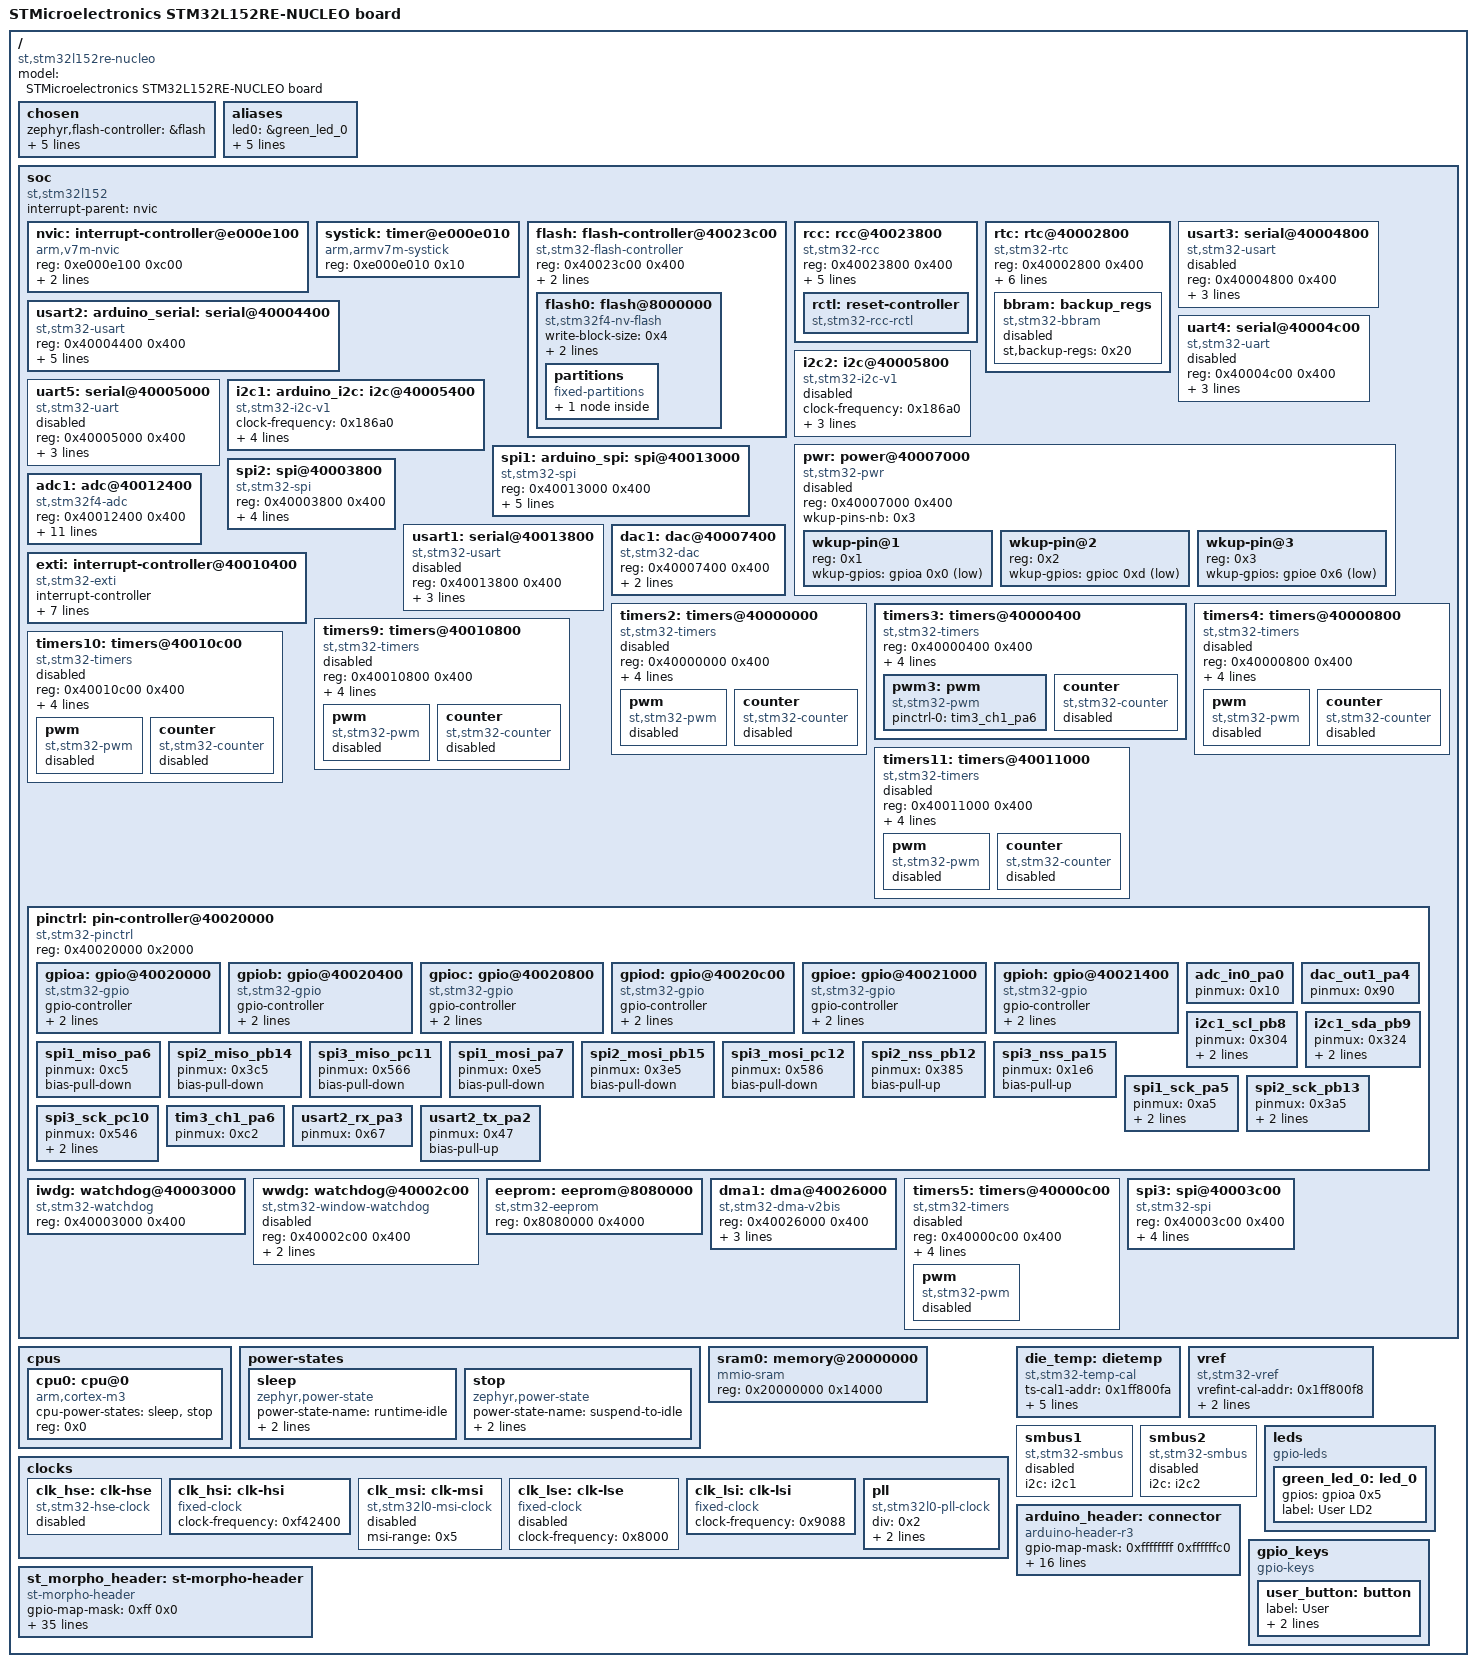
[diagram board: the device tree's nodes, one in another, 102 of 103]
/dts-v1/;

/* node '/' defined in zephyr\dts\common\skeleton.dtsi:9 */
/ {
	#address-cells = < 0x1 >;                              /* in zephyr\dts\common\skeleton.dtsi:10 */
	#size-cells = < 0x1 >;                                 /* in zephyr\dts\common\skeleton.dtsi:11 */
	model = "STMicroelectronics STM32L152RE-NUCLEO board"; /* in zephyr\boards\st\nucleo_l152re\nucleo_l152re.dts:15 */
	compatible = "st,stm32l152re-nucleo";                  /* in zephyr\boards\st\nucleo_l152re\nucleo_l152re.dts:16 */

	/* node '/chosen' defined in zephyr\dts\common\skeleton.dtsi:13 */
	chosen {
		zephyr,flash-controller = &flash;  /* in zephyr\dts\arm\st\l1\stm32l1.dtsi:24 */
		zephyr,cortex-m-idle-timer = &rtc; /* in zephyr\dts\arm\st\l1\stm32l1.dtsi:25 */
		zephyr,console = &usart2;          /* in zephyr\boards\st\nucleo_l152re\nucleo_l152re.dts:19 */
		zephyr,shell-uart = &usart2;       /* in zephyr\boards\st\nucleo_l152re\nucleo_l152re.dts:20 */
		zephyr,sram = &sram0;              /* in zephyr\boards\st\nucleo_l152re\nucleo_l152re.dts:21 */
		zephyr,flash = &flash0;            /* in zephyr\boards\st\nucleo_l152re\nucleo_l152re.dts:22 */
	};

	/* node '/aliases' defined in zephyr\dts\common\skeleton.dtsi:15 */
	aliases {
		led0 = &green_led_0;   /* in zephyr\boards\st\nucleo_l152re\nucleo_l152re.dts:45 */
		sw0 = &user_button;    /* in zephyr\boards\st\nucleo_l152re\nucleo_l152re.dts:46 */
		eeprom-0 = &eeprom;    /* in zephyr\boards\st\nucleo_l152re\nucleo_l152re.dts:47 */
		watchdog0 = &iwdg;     /* in zephyr\boards\st\nucleo_l152re\nucleo_l152re.dts:48 */
		die-temp0 = &die_temp; /* in zephyr\boards\st\nucleo_l152re\nucleo_l152re.dts:49 */
		volt-sensor0 = &vref;  /* in zephyr\boards\st\nucleo_l152re\nucleo_l152re.dts:50 */
	};

	/* node '/soc' defined in zephyr\dts\arm\armv7-m.dtsi:6 */
	soc {
		#address-cells = < 0x1 >;     /* in zephyr\dts\arm\armv7-m.dtsi:7 */
		#size-cells = < 0x1 >;        /* in zephyr\dts\arm\armv7-m.dtsi:8 */
		interrupt-parent = < &nvic >; /* in zephyr\dts\arm\armv7-m.dtsi:10 */
		ranges;                       /* in zephyr\dts\arm\armv7-m.dtsi:11 */
		compatible = "st,stm32l152",
		             "st,stm32l1",
		             "simple-bus";    /* in zephyr\dts\arm\st\l1\stm32l152.dtsi:15 */

		/* node '/soc/interrupt-controller@e000e100' defined in zephyr\dts\arm\armv7-m.dtsi:13 */
		nvic: interrupt-controller@e000e100 {
			#address-cells = < 0x1 >;            /* in zephyr\dts\arm\armv7-m.dtsi:14 */
			compatible = "arm,v7m-nvic";         /* in zephyr\dts\arm\armv7-m.dtsi:15 */
			reg = < 0xe000e100 0xc00 >;          /* in zephyr\dts\arm\armv7-m.dtsi:16 */
			interrupt-controller;                /* in zephyr\dts\arm\armv7-m.dtsi:17 */
			#interrupt-cells = < 0x2 >;          /* in zephyr\dts\arm\armv7-m.dtsi:18 */
			arm,num-irq-priority-bits = < 0x4 >; /* in zephyr\dts\arm\st\l1\stm32l1.dtsi:561 */
			phandle = < 0x1 >;                   /* in zephyr\dts\arm\armv7-m.dtsi:10 */
		};

		/* node '/soc/timer@e000e010' defined in zephyr\dts\arm\armv7-m.dtsi:21 */
		systick: timer@e000e010 {
			compatible = "arm,armv7m-systick"; /* in zephyr\dts\arm\armv7-m.dtsi:22 */
			reg = < 0xe000e010 0x10 >;         /* in zephyr\dts\arm\armv7-m.dtsi:23 */
		};

		/* node '/soc/flash-controller@40023c00' defined in zephyr\dts\arm\st\l1\stm32l1.dtsi:103 */
		flash: flash-controller@40023c00 {
			compatible = "st,stm32-flash-controller",
			             "st,stm32f1-flash-controller"; /* in zephyr\dts\arm\st\l1\stm32l1.dtsi:104 */
			reg = < 0x40023c00 0x400 >;                 /* in zephyr\dts\arm\st\l1\stm32l1.dtsi:105 */
			interrupts = < 0x4 0x0 >;                   /* in zephyr\dts\arm\st\l1\stm32l1.dtsi:106 */
			clocks = < &rcc 0x1c 0x8000 >;              /* in zephyr\dts\arm\st\l1\stm32l1.dtsi:107 */
			#address-cells = < 0x1 >;                   /* in zephyr\dts\arm\st\l1\stm32l1.dtsi:109 */
			#size-cells = < 0x1 >;                      /* in zephyr\dts\arm\st\l1\stm32l1.dtsi:110 */

			/* node '/soc/flash-controller@40023c00/flash@8000000' defined in zephyr\dts\arm\st\l1\stm32l1.dtsi:112 */
			flash0: flash@8000000 {
				compatible = "st,stm32f4-nv-flash",
				             "st,stm32-nv-flash",
				             "soc-nv-flash";        /* in zephyr\dts\arm\st\l1\stm32l1.dtsi:113 */
				write-block-size = < 0x4 >;         /* in zephyr\dts\arm\st\l1\stm32l1.dtsi:116 */
				max-erase-time = < 0x4 >;           /* in zephyr\dts\arm\st\l1\stm32l1.dtsi:119 */
				reg = < 0x8000000 0x80000 >;        /* in zephyr\dts\arm\st\l1\stm32l152Xe.dtsi:18 */

				/* node '/soc/flash-controller@40023c00/flash@8000000/partitions' defined in zephyr\boards\st\nucleo_l152re\nucleo_l152re.dts:145 */
				partitions {
					compatible = "fixed-partitions"; /* in zephyr\boards\st\nucleo_l152re\nucleo_l152re.dts:146 */
					#address-cells = < 0x1 >;        /* in zephyr\boards\st\nucleo_l152re\nucleo_l152re.dts:147 */
					#size-cells = < 0x1 >;           /* in zephyr\boards\st\nucleo_l152re\nucleo_l152re.dts:148 */

					/* node '/soc/flash-controller@40023c00/flash@8000000/partitions/partition@7e000' defined in zephyr\boards\st\nucleo_l152re\nucleo_l152re.dts:151 */
					storage_partition: partition@7e000 {
						label = "storage";        /* in zephyr\boards\st\nucleo_l152re\nucleo_l152re.dts:152 */
						reg = < 0x7e000 0x2000 >; /* in zephyr\boards\st\nucleo_l152re\nucleo_l152re.dts:153 */
					};
				};
			};
		};

		/* node '/soc/rcc@40023800' defined in zephyr\dts\arm\st\l1\stm32l1.dtsi:123 */
		rcc: rcc@40023800 {
			compatible = "st,stm32-rcc";     /* in zephyr\dts\arm\st\l1\stm32l1.dtsi:124 */
			#clock-cells = < 0x2 >;          /* in zephyr\dts\arm\st\l1\stm32l1.dtsi:125 */
			reg = < 0x40023800 0x400 >;      /* in zephyr\dts\arm\st\l1\stm32l1.dtsi:126 */
			clocks = < &pll >;               /* in zephyr\boards\st\nucleo_l152re\nucleo_l152re.dts:70 */
			clock-frequency = < 0x1e84800 >; /* in zephyr\boards\st\nucleo_l152re\nucleo_l152re.dts:71 */
			ahb-prescaler = < 0x1 >;         /* in zephyr\boards\st\nucleo_l152re\nucleo_l152re.dts:72 */
			apb1-prescaler = < 0x1 >;        /* in zephyr\boards\st\nucleo_l152re\nucleo_l152re.dts:73 */
			apb2-prescaler = < 0x1 >;        /* in zephyr\boards\st\nucleo_l152re\nucleo_l152re.dts:74 */
			phandle = < 0x2 >;               /* in zephyr\dts\arm\st\l1\stm32l1.dtsi:107 */

			/* node '/soc/rcc@40023800/reset-controller' defined in zephyr\dts\arm\st\l1\stm32l1.dtsi:128 */
			rctl: reset-controller {
				compatible = "st,stm32-rcc-rctl"; /* in zephyr\dts\arm\st\l1\stm32l1.dtsi:129 */
				#reset-cells = < 0x1 >;           /* in zephyr\dts\arm\st\l1\stm32l1.dtsi:130 */
				phandle = < 0x4 >;                /* in zephyr\dts\arm\st\l1\stm32l1.dtsi:149 */
			};
		};

		/* node '/soc/rtc@40002800' defined in zephyr\dts\arm\st\l1\stm32l1.dtsi:134 */
		rtc: rtc@40002800 {
			compatible = "st,stm32-rtc";       /* in zephyr\dts\arm\st\l1\stm32l1.dtsi:135 */
			reg = < 0x40002800 0x400 >;        /* in zephyr\dts\arm\st\l1\stm32l1.dtsi:136 */
			interrupts = < 0x29 0x0 >;         /* in zephyr\dts\arm\st\l1\stm32l1.dtsi:137 */
			prescaler = < 0x8000 >;            /* in zephyr\dts\arm\st\l1\stm32l1.dtsi:139 */
			alarms-count = < 0x2 >;            /* in zephyr\dts\arm\st\l1\stm32l1.dtsi:140 */
			alrm-exti-line = < 0x11 >;         /* in zephyr\dts\arm\st\l1\stm32l1.dtsi:141 */
			clocks = < &rcc 0x24 0x10000000 >,
			         < &rcc 0x3 0x10d00034 >;  /* in zephyr\boards\st\nucleo_l152re\nucleo_l152re.dts:121 */
			status = "okay";                   /* in zephyr\boards\st\nucleo_l152re\nucleo_l152re.dts:123 */

			/* node '/soc/rtc@40002800/backup_regs' defined in zephyr\dts\arm\st\l1\stm32l152Xe.dtsi:55 */
			bbram: backup_regs {
				compatible = "st,stm32-bbram"; /* in zephyr\dts\arm\st\l1\stm32l152Xe.dtsi:56 */
				st,backup-regs = < 0x20 >;     /* in zephyr\dts\arm\st\l1\stm32l152Xe.dtsi:57 */
				status = "disabled";           /* in zephyr\dts\arm\st\l1\stm32l152Xe.dtsi:58 */
			};
		};

		/* node '/soc/serial@40004400' defined in zephyr\dts\arm\st\l1\stm32l1.dtsi:145 */
		usart2: arduino_serial: serial@40004400 {
			compatible = "st,stm32-usart",
			             "st,stm32-uart";                  /* in zephyr\dts\arm\st\l1\stm32l1.dtsi:146 */
			reg = < 0x40004400 0x400 >;                    /* in zephyr\dts\arm\st\l1\stm32l1.dtsi:147 */
			clocks = < &rcc 0x24 0x20000 >;                /* in zephyr\dts\arm\st\l1\stm32l1.dtsi:148 */
			resets = < &rctl 0x311 >;                      /* in zephyr\dts\arm\st\l1\stm32l1.dtsi:149 */
			interrupts = < 0x26 0x0 >;                     /* in zephyr\dts\arm\st\l1\stm32l1.dtsi:150 */
			pinctrl-0 = < &usart2_tx_pa2 &usart2_rx_pa3 >; /* in zephyr\boards\st\nucleo_l152re\nucleo_l152re.dts:78 */
			pinctrl-names = "default";                     /* in zephyr\boards\st\nucleo_l152re\nucleo_l152re.dts:79 */
			current-speed = < 0x1c200 >;                   /* in zephyr\boards\st\nucleo_l152re\nucleo_l152re.dts:80 */
			status = "okay";                               /* in zephyr\boards\st\nucleo_l152re\nucleo_l152re.dts:81 */
		};

		/* node '/soc/serial@40004800' defined in zephyr\dts\arm\st\l1\stm32l1.dtsi:154 */
		usart3: serial@40004800 {
			compatible = "st,stm32-usart",
			             "st,stm32-uart";   /* in zephyr\dts\arm\st\l1\stm32l1.dtsi:155 */
			reg = < 0x40004800 0x400 >;     /* in zephyr\dts\arm\st\l1\stm32l1.dtsi:156 */
			clocks = < &rcc 0x24 0x40000 >; /* in zephyr\dts\arm\st\l1\stm32l1.dtsi:157 */
			resets = < &rctl 0x312 >;       /* in zephyr\dts\arm\st\l1\stm32l1.dtsi:158 */
			interrupts = < 0x27 0x0 >;      /* in zephyr\dts\arm\st\l1\stm32l1.dtsi:159 */
			status = "disabled";            /* in zephyr\dts\arm\st\l1\stm32l1.dtsi:160 */
		};

		/* node '/soc/serial@40004c00' defined in zephyr\dts\arm\st\l1\stm32l1.dtsi:163 */
		uart4: serial@40004c00 {
			compatible = "st,stm32-uart";   /* in zephyr\dts\arm\st\l1\stm32l1.dtsi:164 */
			reg = < 0x40004c00 0x400 >;     /* in zephyr\dts\arm\st\l1\stm32l1.dtsi:165 */
			clocks = < &rcc 0x24 0x80000 >; /* in zephyr\dts\arm\st\l1\stm32l1.dtsi:166 */
			resets = < &rctl 0x313 >;       /* in zephyr\dts\arm\st\l1\stm32l1.dtsi:167 */
			interrupts = < 0x30 0x0 >;      /* in zephyr\dts\arm\st\l1\stm32l1.dtsi:168 */
			status = "disabled";            /* in zephyr\dts\arm\st\l1\stm32l1.dtsi:169 */
		};

		/* node '/soc/serial@40005000' defined in zephyr\dts\arm\st\l1\stm32l1.dtsi:172 */
		uart5: serial@40005000 {
			compatible = "st,stm32-uart";    /* in zephyr\dts\arm\st\l1\stm32l1.dtsi:173 */
			reg = < 0x40005000 0x400 >;      /* in zephyr\dts\arm\st\l1\stm32l1.dtsi:174 */
			clocks = < &rcc 0x24 0x100000 >; /* in zephyr\dts\arm\st\l1\stm32l1.dtsi:175 */
			resets = < &rctl 0x314 >;        /* in zephyr\dts\arm\st\l1\stm32l1.dtsi:176 */
			interrupts = < 0x31 0x0 >;       /* in zephyr\dts\arm\st\l1\stm32l1.dtsi:177 */
			status = "disabled";             /* in zephyr\dts\arm\st\l1\stm32l1.dtsi:178 */
		};

		/* node '/soc/i2c@40005400' defined in zephyr\dts\arm\st\l1\stm32l1.dtsi:181 */
		i2c1: arduino_i2c: i2c@40005400 {
			compatible = "st,stm32-i2c-v1";              /* in zephyr\dts\arm\st\l1\stm32l1.dtsi:182 */
			clock-frequency = < 0x186a0 >;               /* in zephyr\dts\arm\st\l1\stm32l1.dtsi:183 */
			#address-cells = < 0x1 >;                    /* in zephyr\dts\arm\st\l1\stm32l1.dtsi:184 */
			#size-cells = < 0x0 >;                       /* in zephyr\dts\arm\st\l1\stm32l1.dtsi:185 */
			reg = < 0x40005400 0x400 >;                  /* in zephyr\dts\arm\st\l1\stm32l1.dtsi:186 */
			clocks = < &rcc 0x24 0x200000 >;             /* in zephyr\dts\arm\st\l1\stm32l1.dtsi:187 */
			interrupts = < 0x1f 0x0 >,
			             < 0x20 0x0 >;                   /* in zephyr\dts\arm\st\l1\stm32l1.dtsi:188 */
			interrupt-names = "event",
			                  "error";                   /* in zephyr\dts\arm\st\l1\stm32l1.dtsi:189 */
			pinctrl-0 = < &i2c1_scl_pb8 &i2c1_sda_pb9 >; /* in zephyr\boards\st\nucleo_l152re\nucleo_l152re.dts:85 */
			pinctrl-names = "default";                   /* in zephyr\boards\st\nucleo_l152re\nucleo_l152re.dts:86 */
			status = "okay";                             /* in zephyr\boards\st\nucleo_l152re\nucleo_l152re.dts:87 */
			phandle = < 0x1f >;                          /* in zephyr\dts\arm\st\l1\stm32l1.dtsi:547 */
		};

		/* node '/soc/i2c@40005800' defined in zephyr\dts\arm\st\l1\stm32l1.dtsi:193 */
		i2c2: i2c@40005800 {
			compatible = "st,stm32-i2c-v1";  /* in zephyr\dts\arm\st\l1\stm32l1.dtsi:194 */
			clock-frequency = < 0x186a0 >;   /* in zephyr\dts\arm\st\l1\stm32l1.dtsi:195 */
			#address-cells = < 0x1 >;        /* in zephyr\dts\arm\st\l1\stm32l1.dtsi:196 */
			#size-cells = < 0x0 >;           /* in zephyr\dts\arm\st\l1\stm32l1.dtsi:197 */
			reg = < 0x40005800 0x400 >;      /* in zephyr\dts\arm\st\l1\stm32l1.dtsi:198 */
			clocks = < &rcc 0x24 0x400000 >; /* in zephyr\dts\arm\st\l1\stm32l1.dtsi:199 */
			interrupts = < 0x21 0x0 >,
			             < 0x22 0x0 >;       /* in zephyr\dts\arm\st\l1\stm32l1.dtsi:200 */
			interrupt-names = "event",
			                  "error";       /* in zephyr\dts\arm\st\l1\stm32l1.dtsi:201 */
			status = "disabled";             /* in zephyr\dts\arm\st\l1\stm32l1.dtsi:202 */
			phandle = < 0x20 >;              /* in zephyr\dts\arm\st\l1\stm32l1.dtsi:555 */
		};

		/* node '/soc/power@40007000' defined in zephyr\dts\arm\st\l1\stm32l1.dtsi:205 */
		pwr: power@40007000 {
			compatible = "st,stm32-pwr"; /* in zephyr\dts\arm\st\l1\stm32l1.dtsi:206 */
			reg = < 0x40007000 0x400 >;  /* in zephyr\dts\arm\st\l1\stm32l1.dtsi:207 */
			status = "disabled";         /* in zephyr\dts\arm\st\l1\stm32l1.dtsi:208 */
			wkup-pins-nb = < 0x3 >;      /* in zephyr\dts\arm\st\l1\stm32l1.dtsi:210 */
			#address-cells = < 0x1 >;    /* in zephyr\dts\arm\st\l1\stm32l1.dtsi:212 */
			#size-cells = < 0x0 >;       /* in zephyr\dts\arm\st\l1\stm32l1.dtsi:213 */

			/* node '/soc/power@40007000/wkup-pin@1' defined in zephyr\dts\arm\st\l1\stm32l1.dtsi:215 */
			wkup-pin@1 {
				reg = < 0x1 >;                   /* in zephyr\dts\arm\st\l1\stm32l1.dtsi:216 */
				wkup-gpios = < &gpioa 0x0 0x1 >; /* in zephyr\dts\arm\st\l1\stm32l1.dtsi:217 */
			};

			/* node '/soc/power@40007000/wkup-pin@2' defined in zephyr\dts\arm\st\l1\stm32l1.dtsi:220 */
			wkup-pin@2 {
				reg = < 0x2 >;                   /* in zephyr\dts\arm\st\l1\stm32l1.dtsi:221 */
				wkup-gpios = < &gpioc 0xd 0x1 >; /* in zephyr\dts\arm\st\l1\stm32l1.dtsi:222 */
			};

			/* node '/soc/power@40007000/wkup-pin@3' defined in zephyr\dts\arm\st\l1\stm32l1.dtsi:225 */
			wkup-pin@3 {
				reg = < 0x3 >;                   /* in zephyr\dts\arm\st\l1\stm32l1.dtsi:226 */
				wkup-gpios = < &gpioe 0x6 0x1 >; /* in zephyr\dts\arm\st\l1\stm32l1.dtsi:227 */
			};
		};

		/* node '/soc/spi@40013000' defined in zephyr\dts\arm\st\l1\stm32l1.dtsi:231 */
		spi1: arduino_spi: spi@40013000 {
			compatible = "st,stm32-spi";                                 /* in zephyr\dts\arm\st\l1\stm32l1.dtsi:232 */
			#address-cells = < 0x1 >;                                    /* in zephyr\dts\arm\st\l1\stm32l1.dtsi:233 */
			#size-cells = < 0x0 >;                                       /* in zephyr\dts\arm\st\l1\stm32l1.dtsi:234 */
			reg = < 0x40013000 0x400 >;                                  /* in zephyr\dts\arm\st\l1\stm32l1.dtsi:235 */
			clocks = < &rcc 0x20 0x1000 >;                               /* in zephyr\dts\arm\st\l1\stm32l1.dtsi:236 */
			interrupts = < 0x23 0x0 >;                                   /* in zephyr\dts\arm\st\l1\stm32l1.dtsi:237 */
			pinctrl-0 = < &spi1_sck_pa5 &spi1_miso_pa6 &spi1_mosi_pa7 >; /* in zephyr\boards\st\nucleo_l152re\nucleo_l152re.dts:91 */
			pinctrl-names = "default";                                   /* in zephyr\boards\st\nucleo_l152re\nucleo_l152re.dts:92 */
			cs-gpios = < &gpiob 0x6 0x11 >;                              /* in zephyr\boards\st\nucleo_l152re\nucleo_l152re.dts:93 */
			status = "okay";                                             /* in zephyr\boards\st\nucleo_l152re\nucleo_l152re.dts:94 */
		};

		/* node '/soc/spi@40003800' defined in zephyr\dts\arm\st\l1\stm32l1.dtsi:241 */
		spi2: spi@40003800 {
			compatible = "st,stm32-spi";                                                   /* in zephyr\dts\arm\st\l1\stm32l1.dtsi:242 */
			#address-cells = < 0x1 >;                                                      /* in zephyr\dts\arm\st\l1\stm32l1.dtsi:243 */
			#size-cells = < 0x0 >;                                                         /* in zephyr\dts\arm\st\l1\stm32l1.dtsi:244 */
			reg = < 0x40003800 0x400 >;                                                    /* in zephyr\dts\arm\st\l1\stm32l1.dtsi:245 */
			clocks = < &rcc 0x24 0x4000 >;                                                 /* in zephyr\dts\arm\st\l1\stm32l1.dtsi:246 */
			interrupts = < 0x24 0x0 >;                                                     /* in zephyr\dts\arm\st\l1\stm32l1.dtsi:247 */
			pinctrl-0 = < &spi2_nss_pb12 &spi2_sck_pb13 &spi2_miso_pb14 &spi2_mosi_pb15 >; /* in zephyr\boards\st\nucleo_l152re\nucleo_l152re.dts:98 */
			pinctrl-names = "default";                                                     /* in zephyr\boards\st\nucleo_l152re\nucleo_l152re.dts:100 */
			status = "okay";                                                               /* in zephyr\boards\st\nucleo_l152re\nucleo_l152re.dts:101 */
		};

		/* node '/soc/serial@40013800' defined in zephyr\dts\arm\st\l1\stm32l1.dtsi:251 */
		usart1: serial@40013800 {
			compatible = "st,stm32-usart",
			             "st,stm32-uart";  /* in zephyr\dts\arm\st\l1\stm32l1.dtsi:252 */
			reg = < 0x40013800 0x400 >;    /* in zephyr\dts\arm\st\l1\stm32l1.dtsi:253 */
			clocks = < &rcc 0x20 0x4000 >; /* in zephyr\dts\arm\st\l1\stm32l1.dtsi:254 */
			resets = < &rctl 0x28e >;      /* in zephyr\dts\arm\st\l1\stm32l1.dtsi:255 */
			interrupts = < 0x25 0x0 >;     /* in zephyr\dts\arm\st\l1\stm32l1.dtsi:256 */
			status = "disabled";           /* in zephyr\dts\arm\st\l1\stm32l1.dtsi:257 */
		};

		/* node '/soc/adc@40012400' defined in zephyr\dts\arm\st\l1\stm32l1.dtsi:260 */
		adc1: adc@40012400 {
			compatible = "st,stm32f4-adc",
			             "st,stm32-adc";                                 /* in zephyr\dts\arm\st\l1\stm32l1.dtsi:261 */
			reg = < 0x40012400 0x400 >;                                  /* in zephyr\dts\arm\st\l1\stm32l1.dtsi:262 */
			clocks = < &rcc 0x20 0x200 >,
			         < &rcc 0x5 0xff >;                                  /* in zephyr\dts\arm\st\l1\stm32l1.dtsi:263 */
			interrupts = < 0x12 0x0 >;                                   /* in zephyr\dts\arm\st\l1\stm32l1.dtsi:265 */
			#io-channel-cells = < 0x1 >;                                 /* in zephyr\dts\arm\st\l1\stm32l1.dtsi:267 */
			resolutions = < 0x607804 0x517804 0x427804 0x337804 >;       /* in zephyr\dts\arm\st\l1\stm32l1.dtsi:268 */
			sampling-times = < 0x4 0x9 0x10 0x18 0x30 0x60 0xc0 0x180 >; /* in zephyr\dts\arm\st\l1\stm32l1.dtsi:272 */
			st,adc-sequencer = "FULLY_CONFIGURABLE";                     /* in zephyr\dts\arm\st\l1\stm32l1.dtsi:274 */
			st,adc-oversampler = "OVERSAMPLER_NONE";                     /* in zephyr\dts\arm\st\l1\stm32l1.dtsi:275 */
			pinctrl-0 = < &adc_in0_pa0 >;                                /* in zephyr\boards\st\nucleo_l152re\nucleo_l152re.dts:127 */
			pinctrl-names = "default";                                   /* in zephyr\boards\st\nucleo_l152re\nucleo_l152re.dts:128 */
			st,adc-clock-source = "ASYNC";                               /* in zephyr\boards\st\nucleo_l152re\nucleo_l152re.dts:129 */
			st,adc-prescaler = < 0x4 >;                                  /* in zephyr\boards\st\nucleo_l152re\nucleo_l152re.dts:130 */
			status = "okay";                                             /* in zephyr\boards\st\nucleo_l152re\nucleo_l152re.dts:131 */
			phandle = < 0x1e >;                                          /* in zephyr\dts\arm\st\l1\stm32l1.dtsi:531 */
		};

		/* node '/soc/dac@40007400' defined in zephyr\dts\arm\st\l1\stm32l1.dtsi:278 */
		dac1: dac@40007400 {
			compatible = "st,stm32-dac";       /* in zephyr\dts\arm\st\l1\stm32l1.dtsi:279 */
			reg = < 0x40007400 0x400 >;        /* in zephyr\dts\arm\st\l1\stm32l1.dtsi:280 */
			clocks = < &rcc 0x24 0x20000000 >; /* in zephyr\dts\arm\st\l1\stm32l1.dtsi:281 */
			#io-channel-cells = < 0x1 >;       /* in zephyr\dts\arm\st\l1\stm32l1.dtsi:283 */
			status = "okay";                   /* in zephyr\boards\st\nucleo_l152re\nucleo_l152re.dts:139 */
			pinctrl-0 = < &dac_out1_pa4 >;     /* in zephyr\boards\st\nucleo_l152re\nucleo_l152re.dts:140 */
			pinctrl-names = "default";         /* in zephyr\boards\st\nucleo_l152re\nucleo_l152re.dts:141 */
		};

		/* node '/soc/interrupt-controller@40010400' defined in zephyr\dts\arm\st\l1\stm32l1.dtsi:286 */
		exti: interrupt-controller@40010400 {
			compatible = "st,stm32-exti";  /* in zephyr\dts\arm\st\l1\stm32l1.dtsi:287 */
			interrupt-controller;          /* in zephyr\dts\arm\st\l1\stm32l1.dtsi:288 */
			#interrupt-cells = < 0x1 >;    /* in zephyr\dts\arm\st\l1\stm32l1.dtsi:289 */
			#address-cells = < 0x1 >;      /* in zephyr\dts\arm\st\l1\stm32l1.dtsi:290 */
			reg = < 0x40010400 0x400 >;    /* in zephyr\dts\arm\st\l1\stm32l1.dtsi:291 */
			clocks = < &rcc 0x20 0x1 >;    /* in zephyr\dts\arm\st\l1\stm32l1.dtsi:292 */
			num-lines = < 0x20 >;          /* in zephyr\dts\arm\st\l1\stm32l1.dtsi:293 */
			interrupts = < 0x6 0x0 >,
			             < 0x7 0x0 >,
			             < 0x8 0x0 >,
			             < 0x9 0x0 >,
			             < 0xa 0x0 >,
			             < 0x17 0x0 >,
			             < 0x28 0x0 >;     /* in zephyr\dts\arm\st\l1\stm32l1.dtsi:294 */
			interrupt-names = "line0",
			                  "line1",
			                  "line2",
			                  "line3",
			                  "line4",
			                  "line5-9",
			                  "line10-15"; /* in zephyr\dts\arm\st\l1\stm32l1.dtsi:296 */
			line-ranges = < 0x0 0x1 >,
			              < 0x1 0x1 >,
			              < 0x2 0x1 >,
			              < 0x3 0x1 >,
			              < 0x4 0x1 >,
			              < 0x5 0x5 >,
			              < 0xa 0x6 >;     /* in zephyr\dts\arm\st\l1\stm32l1.dtsi:298 */
		};

		/* node '/soc/timers@40000000' defined in zephyr\dts\arm\st\l1\stm32l1.dtsi:302 */
		timers2: timers@40000000 {
			compatible = "st,stm32-timers"; /* in zephyr\dts\arm\st\l1\stm32l1.dtsi:303 */
			reg = < 0x40000000 0x400 >;     /* in zephyr\dts\arm\st\l1\stm32l1.dtsi:304 */
			clocks = < &rcc 0x24 0x1 >,
			         < &rcc 0x6 0xff >;     /* in zephyr\dts\arm\st\l1\stm32l1.dtsi:305 */
			resets = < &rctl 0x300 >;       /* in zephyr\dts\arm\st\l1\stm32l1.dtsi:307 */
			interrupts = < 0x1c 0x0 >;      /* in zephyr\dts\arm\st\l1\stm32l1.dtsi:308 */
			interrupt-names = "global";     /* in zephyr\dts\arm\st\l1\stm32l1.dtsi:309 */
			st,prescaler = < 0x0 >;         /* in zephyr\dts\arm\st\l1\stm32l1.dtsi:310 */
			status = "disabled";            /* in zephyr\dts\arm\st\l1\stm32l1.dtsi:311 */

			/* node '/soc/timers@40000000/pwm' defined in zephyr\dts\arm\st\l1\stm32l1.dtsi:313 */
			pwm {
				compatible = "st,stm32-pwm"; /* in zephyr\dts\arm\st\l1\stm32l1.dtsi:314 */
				status = "disabled";         /* in zephyr\dts\arm\st\l1\stm32l1.dtsi:315 */
				#pwm-cells = < 0x3 >;        /* in zephyr\dts\arm\st\l1\stm32l1.dtsi:316 */
			};

			/* node '/soc/timers@40000000/counter' defined in zephyr\dts\arm\st\l1\stm32l1.dtsi:319 */
			counter {
				compatible = "st,stm32-counter"; /* in zephyr\dts\arm\st\l1\stm32l1.dtsi:320 */
				status = "disabled";             /* in zephyr\dts\arm\st\l1\stm32l1.dtsi:321 */
			};
		};

		/* node '/soc/timers@40000400' defined in zephyr\dts\arm\st\l1\stm32l1.dtsi:325 */
		timers3: timers@40000400 {
			compatible = "st,stm32-timers"; /* in zephyr\dts\arm\st\l1\stm32l1.dtsi:326 */
			reg = < 0x40000400 0x400 >;     /* in zephyr\dts\arm\st\l1\stm32l1.dtsi:327 */
			clocks = < &rcc 0x24 0x2 >,
			         < &rcc 0x6 0xff >;     /* in zephyr\dts\arm\st\l1\stm32l1.dtsi:328 */
			resets = < &rctl 0x301 >;       /* in zephyr\dts\arm\st\l1\stm32l1.dtsi:330 */
			interrupts = < 0x1d 0x0 >;      /* in zephyr\dts\arm\st\l1\stm32l1.dtsi:331 */
			interrupt-names = "global";     /* in zephyr\dts\arm\st\l1\stm32l1.dtsi:332 */
			st,prescaler = < 0x0 >;         /* in zephyr\dts\arm\st\l1\stm32l1.dtsi:333 */
			status = "okay";                /* in zephyr\boards\st\nucleo_l152re\nucleo_l152re.dts:159 */

			/* node '/soc/timers@40000400/pwm' defined in zephyr\dts\arm\st\l1\stm32l1.dtsi:336 */
			pwm3: pwm {
				compatible = "st,stm32-pwm";   /* in zephyr\dts\arm\st\l1\stm32l1.dtsi:337 */
				#pwm-cells = < 0x3 >;          /* in zephyr\dts\arm\st\l1\stm32l1.dtsi:339 */
				status = "okay";               /* in zephyr\boards\st\nucleo_l152re\nucleo_l152re.dts:162 */
				pinctrl-0 = < &tim3_ch1_pa6 >; /* in zephyr\boards\st\nucleo_l152re\nucleo_l152re.dts:163 */
				pinctrl-names = "default";     /* in zephyr\boards\st\nucleo_l152re\nucleo_l152re.dts:164 */
			};

			/* node '/soc/timers@40000400/counter' defined in zephyr\dts\arm\st\l1\stm32l1.dtsi:342 */
			counter {
				compatible = "st,stm32-counter"; /* in zephyr\dts\arm\st\l1\stm32l1.dtsi:343 */
				status = "disabled";             /* in zephyr\dts\arm\st\l1\stm32l1.dtsi:344 */
			};
		};

		/* node '/soc/timers@40000800' defined in zephyr\dts\arm\st\l1\stm32l1.dtsi:348 */
		timers4: timers@40000800 {
			compatible = "st,stm32-timers"; /* in zephyr\dts\arm\st\l1\stm32l1.dtsi:349 */
			reg = < 0x40000800 0x400 >;     /* in zephyr\dts\arm\st\l1\stm32l1.dtsi:350 */
			clocks = < &rcc 0x24 0x4 >,
			         < &rcc 0x6 0xff >;     /* in zephyr\dts\arm\st\l1\stm32l1.dtsi:351 */
			resets = < &rctl 0x302 >;       /* in zephyr\dts\arm\st\l1\stm32l1.dtsi:353 */
			interrupts = < 0x1e 0x0 >;      /* in zephyr\dts\arm\st\l1\stm32l1.dtsi:354 */
			interrupt-names = "global";     /* in zephyr\dts\arm\st\l1\stm32l1.dtsi:355 */
			st,prescaler = < 0x0 >;         /* in zephyr\dts\arm\st\l1\stm32l1.dtsi:356 */
			status = "disabled";            /* in zephyr\dts\arm\st\l1\stm32l1.dtsi:357 */

			/* node '/soc/timers@40000800/pwm' defined in zephyr\dts\arm\st\l1\stm32l1.dtsi:359 */
			pwm {
				compatible = "st,stm32-pwm"; /* in zephyr\dts\arm\st\l1\stm32l1.dtsi:360 */
				status = "disabled";         /* in zephyr\dts\arm\st\l1\stm32l1.dtsi:361 */
				#pwm-cells = < 0x3 >;        /* in zephyr\dts\arm\st\l1\stm32l1.dtsi:362 */
			};

			/* node '/soc/timers@40000800/counter' defined in zephyr\dts\arm\st\l1\stm32l1.dtsi:365 */
			counter {
				compatible = "st,stm32-counter"; /* in zephyr\dts\arm\st\l1\stm32l1.dtsi:366 */
				status = "disabled";             /* in zephyr\dts\arm\st\l1\stm32l1.dtsi:367 */
			};
		};

		/* node '/soc/timers@40010800' defined in zephyr\dts\arm\st\l1\stm32l1.dtsi:371 */
		timers9: timers@40010800 {
			compatible = "st,stm32-timers"; /* in zephyr\dts\arm\st\l1\stm32l1.dtsi:372 */
			reg = < 0x40010800 0x400 >;     /* in zephyr\dts\arm\st\l1\stm32l1.dtsi:373 */
			clocks = < &rcc 0x20 0x4 >,
			         < &rcc 0x7 0xff >;     /* in zephyr\dts\arm\st\l1\stm32l1.dtsi:374 */
			resets = < &rctl 0x282 >;       /* in zephyr\dts\arm\st\l1\stm32l1.dtsi:376 */
			interrupts = < 0x19 0x0 >;      /* in zephyr\dts\arm\st\l1\stm32l1.dtsi:377 */
			interrupt-names = "global";     /* in zephyr\dts\arm\st\l1\stm32l1.dtsi:378 */
			st,prescaler = < 0x0 >;         /* in zephyr\dts\arm\st\l1\stm32l1.dtsi:379 */
			status = "disabled";            /* in zephyr\dts\arm\st\l1\stm32l1.dtsi:380 */

			/* node '/soc/timers@40010800/pwm' defined in zephyr\dts\arm\st\l1\stm32l1.dtsi:382 */
			pwm {
				compatible = "st,stm32-pwm"; /* in zephyr\dts\arm\st\l1\stm32l1.dtsi:383 */
				status = "disabled";         /* in zephyr\dts\arm\st\l1\stm32l1.dtsi:384 */
				#pwm-cells = < 0x3 >;        /* in zephyr\dts\arm\st\l1\stm32l1.dtsi:385 */
			};

			/* node '/soc/timers@40010800/counter' defined in zephyr\dts\arm\st\l1\stm32l1.dtsi:388 */
			counter {
				compatible = "st,stm32-counter"; /* in zephyr\dts\arm\st\l1\stm32l1.dtsi:389 */
				status = "disabled";             /* in zephyr\dts\arm\st\l1\stm32l1.dtsi:390 */
			};
		};

		/* node '/soc/timers@40010c00' defined in zephyr\dts\arm\st\l1\stm32l1.dtsi:394 */
		timers10: timers@40010c00 {
			compatible = "st,stm32-timers"; /* in zephyr\dts\arm\st\l1\stm32l1.dtsi:395 */
			reg = < 0x40010c00 0x400 >;     /* in zephyr\dts\arm\st\l1\stm32l1.dtsi:396 */
			clocks = < &rcc 0x20 0x8 >,
			         < &rcc 0x7 0xff >;     /* in zephyr\dts\arm\st\l1\stm32l1.dtsi:397 */
			resets = < &rctl 0x283 >;       /* in zephyr\dts\arm\st\l1\stm32l1.dtsi:399 */
			interrupts = < 0x1a 0x0 >;      /* in zephyr\dts\arm\st\l1\stm32l1.dtsi:400 */
			interrupt-names = "global";     /* in zephyr\dts\arm\st\l1\stm32l1.dtsi:401 */
			st,prescaler = < 0x0 >;         /* in zephyr\dts\arm\st\l1\stm32l1.dtsi:402 */
			status = "disabled";            /* in zephyr\dts\arm\st\l1\stm32l1.dtsi:403 */

			/* node '/soc/timers@40010c00/pwm' defined in zephyr\dts\arm\st\l1\stm32l1.dtsi:405 */
			pwm {
				compatible = "st,stm32-pwm"; /* in zephyr\dts\arm\st\l1\stm32l1.dtsi:406 */
				status = "disabled";         /* in zephyr\dts\arm\st\l1\stm32l1.dtsi:407 */
				#pwm-cells = < 0x3 >;        /* in zephyr\dts\arm\st\l1\stm32l1.dtsi:408 */
			};

			/* node '/soc/timers@40010c00/counter' defined in zephyr\dts\arm\st\l1\stm32l1.dtsi:411 */
			counter {
				compatible = "st,stm32-counter"; /* in zephyr\dts\arm\st\l1\stm32l1.dtsi:412 */
				status = "disabled";             /* in zephyr\dts\arm\st\l1\stm32l1.dtsi:413 */
			};
		};

		/* node '/soc/timers@40011000' defined in zephyr\dts\arm\st\l1\stm32l1.dtsi:417 */
		timers11: timers@40011000 {
			compatible = "st,stm32-timers"; /* in zephyr\dts\arm\st\l1\stm32l1.dtsi:418 */
			reg = < 0x40011000 0x400 >;     /* in zephyr\dts\arm\st\l1\stm32l1.dtsi:419 */
			clocks = < &rcc 0x20 0x10 >,
			         < &rcc 0x7 0xff >;     /* in zephyr\dts\arm\st\l1\stm32l1.dtsi:420 */
			resets = < &rctl 0x284 >;       /* in zephyr\dts\arm\st\l1\stm32l1.dtsi:422 */
			interrupts = < 0x1b 0x0 >;      /* in zephyr\dts\arm\st\l1\stm32l1.dtsi:423 */
			interrupt-names = "global";     /* in zephyr\dts\arm\st\l1\stm32l1.dtsi:424 */
			st,prescaler = < 0x0 >;         /* in zephyr\dts\arm\st\l1\stm32l1.dtsi:425 */
			status = "disabled";            /* in zephyr\dts\arm\st\l1\stm32l1.dtsi:426 */

			/* node '/soc/timers@40011000/pwm' defined in zephyr\dts\arm\st\l1\stm32l1.dtsi:428 */
			pwm {
				compatible = "st,stm32-pwm"; /* in zephyr\dts\arm\st\l1\stm32l1.dtsi:429 */
				status = "disabled";         /* in zephyr\dts\arm\st\l1\stm32l1.dtsi:430 */
				#pwm-cells = < 0x3 >;        /* in zephyr\dts\arm\st\l1\stm32l1.dtsi:431 */
			};

			/* node '/soc/timers@40011000/counter' defined in zephyr\dts\arm\st\l1\stm32l1.dtsi:434 */
			counter {
				compatible = "st,stm32-counter"; /* in zephyr\dts\arm\st\l1\stm32l1.dtsi:435 */
				status = "disabled";             /* in zephyr\dts\arm\st\l1\stm32l1.dtsi:436 */
			};
		};

		/* node '/soc/pin-controller@40020000' defined in zephyr\dts\arm\st\l1\stm32l1.dtsi:440 */
		pinctrl: pin-controller@40020000 {
			compatible = "st,stm32-pinctrl"; /* in zephyr\dts\arm\st\l1\stm32l1.dtsi:441 */
			#address-cells = < 0x1 >;        /* in zephyr\dts\arm\st\l1\stm32l1.dtsi:442 */
			#size-cells = < 0x1 >;           /* in zephyr\dts\arm\st\l1\stm32l1.dtsi:443 */
			reg = < 0x40020000 0x2000 >;     /* in zephyr\dts\arm\st\l1\stm32l1.dtsi:444 */

			/* node '/soc/pin-controller@40020000/gpio@40020000' defined in zephyr\dts\arm\st\l1\stm32l1.dtsi:446 */
			gpioa: gpio@40020000 {
				compatible = "st,stm32-gpio"; /* in zephyr\dts\arm\st\l1\stm32l1.dtsi:447 */
				gpio-controller;              /* in zephyr\dts\arm\st\l1\stm32l1.dtsi:448 */
				#gpio-cells = < 0x2 >;        /* in zephyr\dts\arm\st\l1\stm32l1.dtsi:449 */
				reg = < 0x40020000 0x400 >;   /* in zephyr\dts\arm\st\l1\stm32l1.dtsi:450 */
				clocks = < &rcc 0x1c 0x1 >;   /* in zephyr\dts\arm\st\l1\stm32l1.dtsi:451 */
				phandle = < 0x9 >;            /* in zephyr\dts\arm\st\l1\stm32l1.dtsi:217 */
			};

			/* node '/soc/pin-controller@40020000/gpio@40020400' defined in zephyr\dts\arm\st\l1\stm32l1.dtsi:454 */
			gpiob: gpio@40020400 {
				compatible = "st,stm32-gpio"; /* in zephyr\dts\arm\st\l1\stm32l1.dtsi:455 */
				gpio-controller;              /* in zephyr\dts\arm\st\l1\stm32l1.dtsi:456 */
				#gpio-cells = < 0x2 >;        /* in zephyr\dts\arm\st\l1\stm32l1.dtsi:457 */
				reg = < 0x40020400 0x400 >;   /* in zephyr\dts\arm\st\l1\stm32l1.dtsi:458 */
				clocks = < &rcc 0x1c 0x2 >;   /* in zephyr\dts\arm\st\l1\stm32l1.dtsi:459 */
				phandle = < 0xf >;            /* in zephyr\boards\st\nucleo_l152re\nucleo_l152re.dts:93 */
			};

			/* node '/soc/pin-controller@40020000/gpio@40020800' defined in zephyr\dts\arm\st\l1\stm32l1.dtsi:462 */
			gpioc: gpio@40020800 {
				compatible = "st,stm32-gpio"; /* in zephyr\dts\arm\st\l1\stm32l1.dtsi:463 */
				gpio-controller;              /* in zephyr\dts\arm\st\l1\stm32l1.dtsi:464 */
				#gpio-cells = < 0x2 >;        /* in zephyr\dts\arm\st\l1\stm32l1.dtsi:465 */
				reg = < 0x40020800 0x400 >;   /* in zephyr\dts\arm\st\l1\stm32l1.dtsi:466 */
				clocks = < &rcc 0x1c 0x4 >;   /* in zephyr\dts\arm\st\l1\stm32l1.dtsi:467 */
				phandle = < 0xa >;            /* in zephyr\dts\arm\st\l1\stm32l1.dtsi:222 */
			};

			/* node '/soc/pin-controller@40020000/gpio@40020c00' defined in zephyr\dts\arm\st\l1\stm32l1.dtsi:470 */
			gpiod: gpio@40020c00 {
				compatible = "st,stm32-gpio"; /* in zephyr\dts\arm\st\l1\stm32l1.dtsi:471 */
				gpio-controller;              /* in zephyr\dts\arm\st\l1\stm32l1.dtsi:472 */
				#gpio-cells = < 0x2 >;        /* in zephyr\dts\arm\st\l1\stm32l1.dtsi:473 */
				reg = < 0x40020c00 0x400 >;   /* in zephyr\dts\arm\st\l1\stm32l1.dtsi:474 */
				clocks = < &rcc 0x1c 0x8 >;   /* in zephyr\dts\arm\st\l1\stm32l1.dtsi:475 */
				phandle = < 0x21 >;           /* in zephyr\boards\st\nucleo_l152re\st_morpho_connector.dtsi:15 */
			};

			/* node '/soc/pin-controller@40020000/gpio@40021000' defined in zephyr\dts\arm\st\l1\stm32l1.dtsi:478 */
			gpioe: gpio@40021000 {
				compatible = "st,stm32-gpio"; /* in zephyr\dts\arm\st\l1\stm32l1.dtsi:479 */
				gpio-controller;              /* in zephyr\dts\arm\st\l1\stm32l1.dtsi:480 */
				#gpio-cells = < 0x2 >;        /* in zephyr\dts\arm\st\l1\stm32l1.dtsi:481 */
				reg = < 0x40021000 0x400 >;   /* in zephyr\dts\arm\st\l1\stm32l1.dtsi:482 */
				clocks = < &rcc 0x1c 0x10 >;  /* in zephyr\dts\arm\st\l1\stm32l1.dtsi:483 */
				phandle = < 0xb >;            /* in zephyr\dts\arm\st\l1\stm32l1.dtsi:227 */
			};

			/* node '/soc/pin-controller@40020000/gpio@40021400' defined in zephyr\dts\arm\st\l1\stm32l1.dtsi:486 */
			gpioh: gpio@40021400 {
				compatible = "st,stm32-gpio"; /* in zephyr\dts\arm\st\l1\stm32l1.dtsi:487 */
				gpio-controller;              /* in zephyr\dts\arm\st\l1\stm32l1.dtsi:488 */
				#gpio-cells = < 0x2 >;        /* in zephyr\dts\arm\st\l1\stm32l1.dtsi:489 */
				reg = < 0x40021400 0x400 >;   /* in zephyr\dts\arm\st\l1\stm32l1.dtsi:490 */
				clocks = < &rcc 0x1c 0x20 >;  /* in zephyr\dts\arm\st\l1\stm32l1.dtsi:491 */
				phandle = < 0x22 >;           /* in zephyr\boards\st\nucleo_l152re\st_morpho_connector.dtsi:15 */
			};

			/* node '/soc/pin-controller@40020000/adc_in0_pa0' defined in modules\hal\stm32\dts\st\l1\stm32l152retx-pinctrl.dtsi:15 */
			adc_in0_pa0: adc_in0_pa0 {
				pinmux = < 0x10 >;  /* in modules\hal\stm32\dts\st\l1\stm32l152retx-pinctrl.dtsi:16 */
				phandle = < 0x14 >; /* in zephyr\boards\st\nucleo_l152re\nucleo_l152re.dts:127 */
			};

			/* node '/soc/pin-controller@40020000/dac_out1_pa4' defined in modules\hal\stm32\dts\st\l1\stm32l152retx-pinctrl.dtsi:405 */
			dac_out1_pa4: dac_out1_pa4 {
				pinmux = < 0x90 >;  /* in modules\hal\stm32\dts\st\l1\stm32l152retx-pinctrl.dtsi:406 */
				phandle = < 0x15 >; /* in zephyr\boards\st\nucleo_l152re\nucleo_l152re.dts:140 */
			};

			/* node '/soc/pin-controller@40020000/i2c1_scl_pb8' defined in modules\hal\stm32\dts\st\l1\stm32l152retx-pinctrl.dtsi:421 */
			i2c1_scl_pb8: i2c1_scl_pb8 {
				pinmux = < 0x304 >; /* in modules\hal\stm32\dts\st\l1\stm32l152retx-pinctrl.dtsi:422 */
				bias-pull-up;       /* in modules\hal\stm32\dts\st\l1\stm32l152retx-pinctrl.dtsi:423 */
				drive-open-drain;   /* in modules\hal\stm32\dts\st\l1\stm32l152retx-pinctrl.dtsi:424 */
				phandle = < 0x7 >;  /* in zephyr\boards\st\nucleo_l152re\nucleo_l152re.dts:85 */
			};

			/* node '/soc/pin-controller@40020000/i2c1_sda_pb9' defined in modules\hal\stm32\dts\st\l1\stm32l152retx-pinctrl.dtsi:441 */
			i2c1_sda_pb9: i2c1_sda_pb9 {
				pinmux = < 0x324 >; /* in modules\hal\stm32\dts\st\l1\stm32l152retx-pinctrl.dtsi:442 */
				bias-pull-up;       /* in modules\hal\stm32\dts\st\l1\stm32l152retx-pinctrl.dtsi:443 */
				drive-open-drain;   /* in modules\hal\stm32\dts\st\l1\stm32l152retx-pinctrl.dtsi:444 */
				phandle = < 0x8 >;  /* in zephyr\boards\st\nucleo_l152re\nucleo_l152re.dts:85 */
			};

			/* node '/soc/pin-controller@40020000/spi1_miso_pa6' defined in modules\hal\stm32\dts\st\l1\stm32l152retx-pinctrl.dtsi:579 */
			spi1_miso_pa6: spi1_miso_pa6 {
				pinmux = < 0xc5 >; /* in modules\hal\stm32\dts\st\l1\stm32l152retx-pinctrl.dtsi:580 */
				bias-pull-down;    /* in modules\hal\stm32\dts\st\l1\stm32l152retx-pinctrl.dtsi:581 */
				phandle = < 0xd >; /* in zephyr\boards\st\nucleo_l152re\nucleo_l152re.dts:91 */
			};

			/* node '/soc/pin-controller@40020000/spi2_miso_pb14' defined in modules\hal\stm32\dts\st\l1\stm32l152retx-pinctrl.dtsi:594 */
			spi2_miso_pb14: spi2_miso_pb14 {
				pinmux = < 0x3c5 >; /* in modules\hal\stm32\dts\st\l1\stm32l152retx-pinctrl.dtsi:595 */
				bias-pull-down;     /* in modules\hal\stm32\dts\st\l1\stm32l152retx-pinctrl.dtsi:596 */
				phandle = < 0x12 >; /* in zephyr\boards\st\nucleo_l152re\nucleo_l152re.dts:98 */
			};

			/* node '/soc/pin-controller@40020000/spi3_miso_pc11' defined in modules\hal\stm32\dts\st\l1\stm32l152retx-pinctrl.dtsi:604 */
			spi3_miso_pc11: spi3_miso_pc11 {
				pinmux = < 0x566 >; /* in modules\hal\stm32\dts\st\l1\stm32l152retx-pinctrl.dtsi:605 */
				bias-pull-down;     /* in modules\hal\stm32\dts\st\l1\stm32l152retx-pinctrl.dtsi:606 */
				phandle = < 0x19 >; /* in zephyr\boards\st\nucleo_l152re\nucleo_l152re.dts:106 */
			};

			/* node '/soc/pin-controller@40020000/spi1_mosi_pa7' defined in modules\hal\stm32\dts\st\l1\stm32l152retx-pinctrl.dtsi:611 */
			spi1_mosi_pa7: spi1_mosi_pa7 {
				pinmux = < 0xe5 >; /* in modules\hal\stm32\dts\st\l1\stm32l152retx-pinctrl.dtsi:612 */
				bias-pull-down;    /* in modules\hal\stm32\dts\st\l1\stm32l152retx-pinctrl.dtsi:613 */
				phandle = < 0xe >; /* in zephyr\boards\st\nucleo_l152re\nucleo_l152re.dts:91 */
			};

			/* node '/soc/pin-controller@40020000/spi2_mosi_pb15' defined in modules\hal\stm32\dts\st\l1\stm32l152retx-pinctrl.dtsi:626 */
			spi2_mosi_pb15: spi2_mosi_pb15 {
				pinmux = < 0x3e5 >; /* in modules\hal\stm32\dts\st\l1\stm32l152retx-pinctrl.dtsi:627 */
				bias-pull-down;     /* in modules\hal\stm32\dts\st\l1\stm32l152retx-pinctrl.dtsi:628 */
				phandle = < 0x13 >; /* in zephyr\boards\st\nucleo_l152re\nucleo_l152re.dts:98 */
			};

			/* node '/soc/pin-controller@40020000/spi3_mosi_pc12' defined in modules\hal\stm32\dts\st\l1\stm32l152retx-pinctrl.dtsi:636 */
			spi3_mosi_pc12: spi3_mosi_pc12 {
				pinmux = < 0x586 >; /* in modules\hal\stm32\dts\st\l1\stm32l152retx-pinctrl.dtsi:637 */
				bias-pull-down;     /* in modules\hal\stm32\dts\st\l1\stm32l152retx-pinctrl.dtsi:638 */
				phandle = < 0x1a >; /* in zephyr\boards\st\nucleo_l152re\nucleo_l152re.dts:106 */
			};

			/* node '/soc/pin-controller@40020000/spi2_nss_pb12' defined in modules\hal\stm32\dts\st\l1\stm32l152retx-pinctrl.dtsi:653 */
			spi2_nss_pb12: spi2_nss_pb12 {
				pinmux = < 0x385 >; /* in modules\hal\stm32\dts\st\l1\stm32l152retx-pinctrl.dtsi:654 */
				bias-pull-up;       /* in modules\hal\stm32\dts\st\l1\stm32l152retx-pinctrl.dtsi:655 */
				phandle = < 0x10 >; /* in zephyr\boards\st\nucleo_l152re\nucleo_l152re.dts:98 */
			};

			/* node '/soc/pin-controller@40020000/spi3_nss_pa15' defined in modules\hal\stm32\dts\st\l1\stm32l152retx-pinctrl.dtsi:663 */
			spi3_nss_pa15: spi3_nss_pa15 {
				pinmux = < 0x1e6 >; /* in modules\hal\stm32\dts\st\l1\stm32l152retx-pinctrl.dtsi:664 */
				bias-pull-up;       /* in modules\hal\stm32\dts\st\l1\stm32l152retx-pinctrl.dtsi:665 */
				phandle = < 0x17 >; /* in zephyr\boards\st\nucleo_l152re\nucleo_l152re.dts:106 */
			};

			/* node '/soc/pin-controller@40020000/spi1_sck_pa5' defined in modules\hal\stm32\dts\st\l1\stm32l152retx-pinctrl.dtsi:670 */
			spi1_sck_pa5: spi1_sck_pa5 {
				pinmux = < 0xa5 >;             /* in modules\hal\stm32\dts\st\l1\stm32l152retx-pinctrl.dtsi:671 */
				bias-pull-down;                /* in modules\hal\stm32\dts\st\l1\stm32l152retx-pinctrl.dtsi:672 */
				slew-rate = "very-high-speed"; /* in modules\hal\stm32\dts\st\l1\stm32l152retx-pinctrl.dtsi:673 */
				phandle = < 0xc >;             /* in zephyr\boards\st\nucleo_l152re\nucleo_l152re.dts:91 */
			};

			/* node '/soc/pin-controller@40020000/spi2_sck_pb13' defined in modules\hal\stm32\dts\st\l1\stm32l152retx-pinctrl.dtsi:682 */
			spi2_sck_pb13: spi2_sck_pb13 {
				pinmux = < 0x3a5 >;            /* in modules\hal\stm32\dts\st\l1\stm32l152retx-pinctrl.dtsi:683 */
				bias-pull-down;                /* in modules\hal\stm32\dts\st\l1\stm32l152retx-pinctrl.dtsi:684 */
				slew-rate = "very-high-speed"; /* in modules\hal\stm32\dts\st\l1\stm32l152retx-pinctrl.dtsi:685 */
				phandle = < 0x11 >;            /* in zephyr\boards\st\nucleo_l152re\nucleo_l152re.dts:98 */
			};

			/* node '/soc/pin-controller@40020000/spi3_sck_pc10' defined in modules\hal\stm32\dts\st\l1\stm32l152retx-pinctrl.dtsi:694 */
			spi3_sck_pc10: spi3_sck_pc10 {
				pinmux = < 0x546 >;            /* in modules\hal\stm32\dts\st\l1\stm32l152retx-pinctrl.dtsi:695 */
				bias-pull-down;                /* in modules\hal\stm32\dts\st\l1\stm32l152retx-pinctrl.dtsi:696 */
				slew-rate = "very-high-speed"; /* in modules\hal\stm32\dts\st\l1\stm32l152retx-pinctrl.dtsi:697 */
				phandle = < 0x18 >;            /* in zephyr\boards\st\nucleo_l152re\nucleo_l152re.dts:106 */
			};

			/* node '/soc/pin-controller@40020000/tim3_ch1_pa6' defined in modules\hal\stm32\dts\st\l1\stm32l152retx-pinctrl.dtsi:762 */
			tim3_ch1_pa6: tim3_ch1_pa6 {
				pinmux = < 0xc2 >;  /* in modules\hal\stm32\dts\st\l1\stm32l152retx-pinctrl.dtsi:763 */
				phandle = < 0x16 >; /* in zephyr\boards\st\nucleo_l152re\nucleo_l152re.dts:163 */
			};

			/* node '/soc/pin-controller@40020000/usart2_rx_pa3' defined in modules\hal\stm32\dts\st\l1\stm32l152retx-pinctrl.dtsi:894 */
			usart2_rx_pa3: usart2_rx_pa3 {
				pinmux = < 0x67 >; /* in modules\hal\stm32\dts\st\l1\stm32l152retx-pinctrl.dtsi:895 */
				phandle = < 0x6 >; /* in zephyr\boards\st\nucleo_l152re\nucleo_l152re.dts:78 */
			};

			/* node '/soc/pin-controller@40020000/usart2_tx_pa2' defined in modules\hal\stm32\dts\st\l1\stm32l152retx-pinctrl.dtsi:926 */
			usart2_tx_pa2: usart2_tx_pa2 {
				pinmux = < 0x47 >; /* in modules\hal\stm32\dts\st\l1\stm32l152retx-pinctrl.dtsi:927 */
				bias-pull-up;      /* in modules\hal\stm32\dts\st\l1\stm32l152retx-pinctrl.dtsi:928 */
				phandle = < 0x5 >; /* in zephyr\boards\st\nucleo_l152re\nucleo_l152re.dts:78 */
			};
		};

		/* node '/soc/watchdog@40003000' defined in zephyr\dts\arm\st\l1\stm32l1.dtsi:495 */
		iwdg: watchdog@40003000 {
			compatible = "st,stm32-watchdog"; /* in zephyr\dts\arm\st\l1\stm32l1.dtsi:496 */
			reg = < 0x40003000 0x400 >;       /* in zephyr\dts\arm\st\l1\stm32l1.dtsi:497 */
			status = "okay";                  /* in zephyr\boards\st\nucleo_l152re\nucleo_l152re.dts:117 */
		};

		/* node '/soc/watchdog@40002c00' defined in zephyr\dts\arm\st\l1\stm32l1.dtsi:501 */
		wwdg: watchdog@40002c00 {
			compatible = "st,stm32-window-watchdog"; /* in zephyr\dts\arm\st\l1\stm32l1.dtsi:502 */
			reg = < 0x40002c00 0x400 >;              /* in zephyr\dts\arm\st\l1\stm32l1.dtsi:503 */
			clocks = < &rcc 0x24 0x800 >;            /* in zephyr\dts\arm\st\l1\stm32l1.dtsi:504 */
			interrupts = < 0x0 0x7 >;                /* in zephyr\dts\arm\st\l1\stm32l1.dtsi:505 */
			status = "disabled";                     /* in zephyr\dts\arm\st\l1\stm32l1.dtsi:506 */
		};

		/* node '/soc/eeprom@8080000' defined in zephyr\dts\arm\st\l1\stm32l1.dtsi:509 */
		eeprom: eeprom@8080000 {
			compatible = "st,stm32-eeprom"; /* in zephyr\dts\arm\st\l1\stm32l1.dtsi:510 */
			reg = < 0x8080000 0x4000 >;     /* in zephyr\dts\arm\st\l1\stm32l152Xe.dtsi:51 */
			status = "okay";                /* in zephyr\boards\st\nucleo_l152re\nucleo_l152re.dts:113 */
		};

		/* node '/soc/dma@40026000' defined in zephyr\dts\arm\st\l1\stm32l1.dtsi:514 */
		dma1: dma@40026000 {
			compatible = "st,stm32-dma-v2bis";                                          /* in zephyr\dts\arm\st\l1\stm32l1.dtsi:515 */
			#dma-cells = < 0x2 >;                                                       /* in zephyr\dts\arm\st\l1\stm32l1.dtsi:516 */
			reg = < 0x40026000 0x400 >;                                                 /* in zephyr\dts\arm\st\l1\stm32l1.dtsi:517 */
			clocks = < &rcc 0x1c 0x1000000 >;                                           /* in zephyr\dts\arm\st\l1\stm32l1.dtsi:518 */
			interrupts = < 0xb 0x0 0xc 0x0 0xd 0x0 0xe 0x0 0xf 0x0 0x10 0x0 0x11 0x0 >; /* in zephyr\dts\arm\st\l1\stm32l1.dtsi:519 */
			status = "okay";                                                            /* in zephyr\boards\st\nucleo_l152re\nucleo_l152re.dts:169 */
		};

		/* node '/soc/timers@40000c00' defined in zephyr\dts\arm\st\l1\stm32l152Xe.dtsi:22 */
		timers5: timers@40000c00 {
			compatible = "st,stm32-timers"; /* in zephyr\dts\arm\st\l1\stm32l152Xe.dtsi:23 */
			reg = < 0x40000c00 0x400 >;     /* in zephyr\dts\arm\st\l1\stm32l152Xe.dtsi:24 */
			clocks = < &rcc 0x24 0x8 >,
			         < &rcc 0x6 0xff >;     /* in zephyr\dts\arm\st\l1\stm32l152Xe.dtsi:25 */
			resets = < &rctl 0x303 >;       /* in zephyr\dts\arm\st\l1\stm32l152Xe.dtsi:27 */
			interrupts = < 0x2d 0x0 >;      /* in zephyr\dts\arm\st\l1\stm32l152Xe.dtsi:28 */
			interrupt-names = "global";     /* in zephyr\dts\arm\st\l1\stm32l152Xe.dtsi:29 */
			st,prescaler = < 0x0 >;         /* in zephyr\dts\arm\st\l1\stm32l152Xe.dtsi:30 */
			status = "disabled";            /* in zephyr\dts\arm\st\l1\stm32l152Xe.dtsi:31 */

			/* node '/soc/timers@40000c00/pwm' defined in zephyr\dts\arm\st\l1\stm32l152Xe.dtsi:33 */
			pwm {
				compatible = "st,stm32-pwm"; /* in zephyr\dts\arm\st\l1\stm32l152Xe.dtsi:34 */
				status = "disabled";         /* in zephyr\dts\arm\st\l1\stm32l152Xe.dtsi:35 */
				#pwm-cells = < 0x3 >;        /* in zephyr\dts\arm\st\l1\stm32l152Xe.dtsi:36 */
			};
		};

		/* node '/soc/spi@40003c00' defined in zephyr\dts\arm\st\l1\stm32l152Xe.dtsi:40 */
		spi3: spi@40003c00 {
			compatible = "st,stm32-spi";                                                   /* in zephyr\dts\arm\st\l1\stm32l152Xe.dtsi:41 */
			#address-cells = < 0x1 >;                                                      /* in zephyr\dts\arm\st\l1\stm32l152Xe.dtsi:42 */
			#size-cells = < 0x0 >;                                                         /* in zephyr\dts\arm\st\l1\stm32l152Xe.dtsi:43 */
			reg = < 0x40003c00 0x400 >;                                                    /* in zephyr\dts\arm\st\l1\stm32l152Xe.dtsi:44 */
			clocks = < &rcc 0x24 0x8000 >;                                                 /* in zephyr\dts\arm\st\l1\stm32l152Xe.dtsi:45 */
			interrupts = < 0x2f 0x0 >;                                                     /* in zephyr\dts\arm\st\l1\stm32l152Xe.dtsi:46 */
			pinctrl-0 = < &spi3_nss_pa15 &spi3_sck_pc10 &spi3_miso_pc11 &spi3_mosi_pc12 >; /* in zephyr\boards\st\nucleo_l152re\nucleo_l152re.dts:106 */
			pinctrl-names = "default";                                                     /* in zephyr\boards\st\nucleo_l152re\nucleo_l152re.dts:108 */
			status = "okay";                                                               /* in zephyr\boards\st\nucleo_l152re\nucleo_l152re.dts:109 */
		};
	};

	/* node '/cpus' defined in zephyr\dts\arm\st\l1\stm32l1.dtsi:28 */
	cpus {
		#address-cells = < 0x1 >; /* in zephyr\dts\arm\st\l1\stm32l1.dtsi:29 */
		#size-cells = < 0x0 >;    /* in zephyr\dts\arm\st\l1\stm32l1.dtsi:30 */

		/* node '/cpus/cpu@0' defined in zephyr\dts\arm\st\l1\stm32l1.dtsi:32 */
		cpu0: cpu@0 {
			device_type = "cpu";                 /* in zephyr\dts\arm\st\l1\stm32l1.dtsi:33 */
			compatible = "arm,cortex-m3";        /* in zephyr\dts\arm\st\l1\stm32l1.dtsi:34 */
			cpu-power-states = < &sleep &stop >; /* in zephyr\dts\arm\st\l1\stm32l1.dtsi:35 */
			reg = < 0x0 >;                       /* in zephyr\dts\arm\st\l1\stm32l1.dtsi:36 */
		};
	};

	/* node '/power-states' defined in zephyr\dts\arm\st\l1\stm32l1.dtsi:40 */
	power-states {

		/* node '/power-states/sleep' defined in zephyr\dts\arm\st\l1\stm32l1.dtsi:41 */
		sleep: sleep {
			compatible = "zephyr,power-state"; /* in zephyr\dts\arm\st\l1\stm32l1.dtsi:42 */
			power-state-name = "runtime-idle"; /* in zephyr\dts\arm\st\l1\stm32l1.dtsi:43 */
			min-residency-us = < 0xf4240 >;    /* in zephyr\dts\arm\st\l1\stm32l1.dtsi:44 */
			exit-latency-us = < 0x2ee >;       /* in zephyr\dts\arm\st\l1\stm32l1.dtsi:45 */
			phandle = < 0x1b >;                /* in zephyr\dts\arm\st\l1\stm32l1.dtsi:35 */
		};

		/* node '/power-states/stop' defined in zephyr\dts\arm\st\l1\stm32l1.dtsi:48 */
		stop: stop {
			compatible = "zephyr,power-state";    /* in zephyr\dts\arm\st\l1\stm32l1.dtsi:49 */
			power-state-name = "suspend-to-idle"; /* in zephyr\dts\arm\st\l1\stm32l1.dtsi:50 */
			min-residency-us = < 0xf4240 >;       /* in zephyr\dts\arm\st\l1\stm32l1.dtsi:51 */
			exit-latency-us = < 0x2ee >;          /* in zephyr\dts\arm\st\l1\stm32l1.dtsi:52 */
			phandle = < 0x1c >;                   /* in zephyr\dts\arm\st\l1\stm32l1.dtsi:35 */
		};
	};

	/* node '/memory@20000000' defined in zephyr\dts\arm\st\l1\stm32l1.dtsi:56 */
	sram0: memory@20000000 {
		compatible = "mmio-sram";     /* in zephyr\dts\arm\st\l1\stm32l1.dtsi:57 */
		reg = < 0x20000000 0x14000 >; /* in zephyr\dts\arm\st\l1\stm32l152Xe.dtsi:12 */
	};

	/* node '/clocks' defined in zephyr\dts\arm\st\l1\stm32l1.dtsi:60 */
	clocks {

		/* node '/clocks/clk-hse' defined in zephyr\dts\arm\st\l1\stm32l1.dtsi:61 */
		clk_hse: clk-hse {
			#clock-cells = < 0x0 >;            /* in zephyr\dts\arm\st\l1\stm32l1.dtsi:62 */
			compatible = "st,stm32-hse-clock"; /* in zephyr\dts\arm\st\l1\stm32l1.dtsi:63 */
			status = "disabled";               /* in zephyr\dts\arm\st\l1\stm32l1.dtsi:64 */
		};

		/* node '/clocks/clk-hsi' defined in zephyr\dts\arm\st\l1\stm32l1.dtsi:67 */
		clk_hsi: clk-hsi {
			#clock-cells = < 0x0 >;         /* in zephyr\dts\arm\st\l1\stm32l1.dtsi:68 */
			compatible = "fixed-clock";     /* in zephyr\dts\arm\st\l1\stm32l1.dtsi:69 */
			clock-frequency = < 0xf42400 >; /* in zephyr\dts\arm\st\l1\stm32l1.dtsi:70 */
			status = "okay";                /* in zephyr\boards\st\nucleo_l152re\nucleo_l152re.dts:59 */
			phandle = < 0x1d >;             /* in zephyr\boards\st\nucleo_l152re\nucleo_l152re.dts:65 */
		};

		/* node '/clocks/clk-msi' defined in zephyr\dts\arm\st\l1\stm32l1.dtsi:74 */
		clk_msi: clk-msi {
			#clock-cells = < 0x0 >;              /* in zephyr\dts\arm\st\l1\stm32l1.dtsi:75 */
			compatible = "st,stm32l0-msi-clock"; /* in zephyr\dts\arm\st\l1\stm32l1.dtsi:76 */
			msi-range = < 0x5 >;                 /* in zephyr\dts\arm\st\l1\stm32l1.dtsi:77 */
			status = "disabled";                 /* in zephyr\dts\arm\st\l1\stm32l1.dtsi:78 */
		};

		/* node '/clocks/clk-lse' defined in zephyr\dts\arm\st\l1\stm32l1.dtsi:81 */
		clk_lse: clk-lse {
			#clock-cells = < 0x0 >;       /* in zephyr\dts\arm\st\l1\stm32l1.dtsi:82 */
			compatible = "fixed-clock";   /* in zephyr\dts\arm\st\l1\stm32l1.dtsi:83 */
			clock-frequency = < 0x8000 >; /* in zephyr\dts\arm\st\l1\stm32l1.dtsi:84 */
			status = "disabled";          /* in zephyr\dts\arm\st\l1\stm32l1.dtsi:85 */
		};

		/* node '/clocks/clk-lsi' defined in zephyr\dts\arm\st\l1\stm32l1.dtsi:88 */
		clk_lsi: clk-lsi {
			#clock-cells = < 0x0 >;       /* in zephyr\dts\arm\st\l1\stm32l1.dtsi:89 */
			compatible = "fixed-clock";   /* in zephyr\dts\arm\st\l1\stm32l1.dtsi:90 */
			clock-frequency = < 0x9088 >; /* in zephyr\dts\arm\st\l1\stm32l1.dtsi:91 */
			status = "okay";              /* in zephyr\boards\st\nucleo_l152re\nucleo_l152re.dts:55 */
		};

		/* node '/clocks/pll' defined in zephyr\dts\arm\st\l1\stm32l1.dtsi:95 */
		pll: pll {
			#clock-cells = < 0x0 >;              /* in zephyr\dts\arm\st\l1\stm32l1.dtsi:96 */
			compatible = "st,stm32l0-pll-clock"; /* in zephyr\dts\arm\st\l1\stm32l1.dtsi:97 */
			div = < 0x2 >;                       /* in zephyr\boards\st\nucleo_l152re\nucleo_l152re.dts:63 */
			mul = < 0x4 >;                       /* in zephyr\boards\st\nucleo_l152re\nucleo_l152re.dts:64 */
			clocks = < &clk_hsi >;               /* in zephyr\boards\st\nucleo_l152re\nucleo_l152re.dts:65 */
			status = "okay";                     /* in zephyr\boards\st\nucleo_l152re\nucleo_l152re.dts:66 */
			phandle = < 0x3 >;                   /* in zephyr\boards\st\nucleo_l152re\nucleo_l152re.dts:70 */
		};
	};

	/* node '/dietemp' defined in zephyr\dts\arm\st\l1\stm32l1.dtsi:524 */
	die_temp: dietemp {
		compatible = "st,stm32-temp-cal"; /* in zephyr\dts\arm\st\l1\stm32l1.dtsi:525 */
		ts-cal1-addr = < 0x1ff800fa >;    /* in zephyr\dts\arm\st\l1\stm32l1.dtsi:526 */
		ts-cal2-addr = < 0x1ff800fe >;    /* in zephyr\dts\arm\st\l1\stm32l1.dtsi:527 */
		ts-cal1-temp = < 0x1e >;          /* in zephyr\dts\arm\st\l1\stm32l1.dtsi:528 */
		ts-cal2-temp = < 0x6e >;          /* in zephyr\dts\arm\st\l1\stm32l1.dtsi:529 */
		ts-cal-vrefanalog = < 0xbb8 >;    /* in zephyr\dts\arm\st\l1\stm32l1.dtsi:530 */
		io-channels = < &adc1 0x10 >;     /* in zephyr\dts\arm\st\l1\stm32l1.dtsi:531 */
		status = "okay";                  /* in zephyr\boards\st\nucleo_l152re\nucleo_l152re.dts:135 */
	};

	/* node '/vref' defined in zephyr\dts\arm\st\l1\stm32l1.dtsi:535 */
	vref: vref {
		compatible = "st,stm32-vref";      /* in zephyr\dts\arm\st\l1\stm32l1.dtsi:536 */
		vrefint-cal-addr = < 0x1ff800f8 >; /* in zephyr\dts\arm\st\l1\stm32l1.dtsi:537 */
		vrefint-cal-mv = < 0xbb8 >;        /* in zephyr\dts\arm\st\l1\stm32l1.dtsi:538 */
		io-channels = < &adc1 0x11 >;      /* in zephyr\dts\arm\st\l1\stm32l1.dtsi:539 */
		status = "okay";                   /* in zephyr\boards\st\nucleo_l152re\nucleo_l152re.dts:173 */
	};

	/* node '/smbus1' defined in zephyr\dts\arm\st\l1\stm32l1.dtsi:543 */
	smbus1: smbus1 {
		compatible = "st,stm32-smbus"; /* in zephyr\dts\arm\st\l1\stm32l1.dtsi:544 */
		#address-cells = < 0x1 >;      /* in zephyr\dts\arm\st\l1\stm32l1.dtsi:545 */
		#size-cells = < 0x0 >;         /* in zephyr\dts\arm\st\l1\stm32l1.dtsi:546 */
		i2c = < &i2c1 >;               /* in zephyr\dts\arm\st\l1\stm32l1.dtsi:547 */
		status = "disabled";           /* in zephyr\dts\arm\st\l1\stm32l1.dtsi:548 */
	};

	/* node '/smbus2' defined in zephyr\dts\arm\st\l1\stm32l1.dtsi:551 */
	smbus2: smbus2 {
		compatible = "st,stm32-smbus"; /* in zephyr\dts\arm\st\l1\stm32l1.dtsi:552 */
		#address-cells = < 0x1 >;      /* in zephyr\dts\arm\st\l1\stm32l1.dtsi:553 */
		#size-cells = < 0x0 >;         /* in zephyr\dts\arm\st\l1\stm32l1.dtsi:554 */
		i2c = < &i2c2 >;               /* in zephyr\dts\arm\st\l1\stm32l1.dtsi:555 */
		status = "disabled";           /* in zephyr\dts\arm\st\l1\stm32l1.dtsi:556 */
	};

	/* node '/connector' defined in zephyr\boards\st\nucleo_l152re\arduino_r3_connector.dtsi:10 */
	arduino_header: connector {
		compatible = "arduino-header-r3";          /* in zephyr\boards\st\nucleo_l152re\arduino_r3_connector.dtsi:11 */
		#gpio-cells = < 0x2 >;                     /* in zephyr\boards\st\nucleo_l152re\arduino_r3_connector.dtsi:12 */
		gpio-map-mask = < 0xffffffff 0xffffffc0 >; /* in zephyr\boards\st\nucleo_l152re\arduino_r3_connector.dtsi:13 */
		gpio-map-pass-thru = < 0x0 0x3f >;         /* in zephyr\boards\st\nucleo_l152re\arduino_r3_connector.dtsi:14 */
		gpio-map = < 0x0 0x0 &gpioa 0x0 0x0 >,
		           < 0x1 0x0 &gpioa 0x1 0x0 >,
		           < 0x2 0x0 &gpioa 0x4 0x0 >,
		           < 0x3 0x0 &gpiob 0x0 0x0 >,
		           < 0x4 0x0 &gpioc 0x1 0x0 >,
		           < 0x5 0x0 &gpioc 0x0 0x0 >,
		           < 0x6 0x0 &gpioa 0x3 0x0 >,
		           < 0x7 0x0 &gpioa 0x2 0x0 >,
		           < 0x8 0x0 &gpioa 0xa 0x0 >,
		           < 0x9 0x0 &gpiob 0x3 0x0 >,
		           < 0xa 0x0 &gpiob 0x5 0x0 >,
		           < 0xb 0x0 &gpiob 0x4 0x0 >,
		           < 0xc 0x0 &gpiob 0xa 0x0 >,
		           < 0xd 0x0 &gpioa 0x8 0x0 >,
		           < 0xe 0x0 &gpioa 0x9 0x0 >,
		           < 0xf 0x0 &gpioc 0x7 0x0 >,
		           < 0x10 0x0 &gpiob 0x6 0x0 >,
		           < 0x11 0x0 &gpioa 0x7 0x0 >,
		           < 0x12 0x0 &gpioa 0x6 0x0 >,
		           < 0x13 0x0 &gpioa 0x5 0x0 >,
		           < 0x14 0x0 &gpiob 0x9 0x0 >,
		           < 0x15 0x0 &gpiob 0x8 0x0 >;    /* in zephyr\boards\st\nucleo_l152re\arduino_r3_connector.dtsi:15 */
	};

	/* node '/st-morpho-header' defined in zephyr\boards\st\nucleo_l152re\st_morpho_connector.dtsi:10 */
	st_morpho_header: st-morpho-header {
		compatible = "st-morpho-header";        /* in zephyr\boards\st\nucleo_l152re\st_morpho_connector.dtsi:11 */
		#gpio-cells = < 0x2 >;                  /* in zephyr\boards\st\nucleo_l152re\st_morpho_connector.dtsi:12 */
		gpio-map-mask = < 0xff 0x0 >;           /* in zephyr\boards\st\nucleo_l152re\st_morpho_connector.dtsi:13 */
		gpio-map-pass-thru = < 0x0 0x7f >;      /* in zephyr\boards\st\nucleo_l152re\st_morpho_connector.dtsi:14 */
		gpio-map = < 0x0 0x0 &gpioc 0xa 0x0 >,
		           < 0x1 0x0 &gpioc 0xb 0x0 >,
		           < 0x2 0x0 &gpioc 0xc 0x0 >,
		           < 0x3 0x0 &gpiod 0x2 0x0 >,
		           < 0xc 0x0 &gpioa 0xd 0x0 >,
		           < 0xe 0x0 &gpioa 0xe 0x0 >,
		           < 0x10 0x0 &gpioa 0xf 0x0 >,
		           < 0x14 0x0 &gpiob 0x7 0x0 >,
		           < 0x16 0x0 &gpioc 0xd 0x0 >,
		           < 0x18 0x0 &gpioc 0xe 0x0 >,
		           < 0x1a 0x0 &gpioc 0xf 0x0 >,
		           < 0x1b 0x0 &gpioa 0x0 0x0 >,
		           < 0x1c 0x0 &gpioh 0x0 0x0 >,
		           < 0x1d 0x0 &gpioa 0x1 0x0 >,
		           < 0x1e 0x0 &gpioh 0x1 0x0 >,
		           < 0x1f 0x0 &gpioa 0x4 0x0 >,
		           < 0x21 0x0 &gpiob 0x0 0x0 >,
		           < 0x22 0x0 &gpioc 0x2 0x0 >,
		           < 0x23 0x0 &gpioc 0x1 0x0 >,
		           < 0x24 0x0 &gpioc 0x3 0x0 >,
		           < 0x25 0x0 &gpioc 0x0 0x0 >,
		           < 0x48 0x0 &gpioc 0x9 0x0 >,
		           < 0x49 0x0 &gpioc 0x8 0x0 >,
		           < 0x4a 0x0 &gpiob 0x8 0x0 >,
		           < 0x4b 0x0 &gpioc 0x6 0x0 >,
		           < 0x4c 0x0 &gpiob 0x9 0x0 >,
		           < 0x4d 0x0 &gpioc 0x5 0x0 >,
		           < 0x52 0x0 &gpioa 0x5 0x0 >,
		           < 0x53 0x0 &gpioa 0xc 0x0 >,
		           < 0x54 0x0 &gpioa 0x6 0x0 >,
		           < 0x55 0x0 &gpioa 0xb 0x0 >,
		           < 0x56 0x0 &gpioa 0x7 0x0 >,
		           < 0x57 0x0 &gpiob 0xc 0x0 >,
		           < 0x58 0x0 &gpiob 0x6 0x0 >,
		           < 0x59 0x0 &gpiob 0xb 0x0 >,
		           < 0x5a 0x0 &gpioc 0x7 0x0 >,
		           < 0x5c 0x0 &gpioa 0x9 0x0 >,
		           < 0x5d 0x0 &gpiob 0x2 0x0 >,
		           < 0x5e 0x0 &gpioa 0x8 0x0 >,
		           < 0x5f 0x0 &gpiob 0x1 0x0 >,
		           < 0x60 0x0 &gpiob 0xa 0x0 >,
		           < 0x61 0x0 &gpiob 0xf 0x0 >,
		           < 0x62 0x0 &gpiob 0x4 0x0 >,
		           < 0x63 0x0 &gpiob 0xe 0x0 >,
		           < 0x64 0x0 &gpiob 0x5 0x0 >,
		           < 0x65 0x0 &gpiob 0xd 0x0 >,
		           < 0x66 0x0 &gpiob 0x3 0x0 >,
		           < 0x68 0x0 &gpioa 0xa 0x0 >,
		           < 0x69 0x0 &gpioc 0x4 0x0 >,
		           < 0x6a 0x0 &gpioa 0x2 0x0 >,
		           < 0x6c 0x0 &gpioa 0x3 0x0 >; /* in zephyr\boards\st\nucleo_l152re\st_morpho_connector.dtsi:15 */
	};

	/* node '/leds' defined in zephyr\boards\st\nucleo_l152re\nucleo_l152re.dts:25 */
	leds: leds {
		compatible = "gpio-leds"; /* in zephyr\boards\st\nucleo_l152re\nucleo_l152re.dts:26 */

		/* node '/leds/led_0' defined in zephyr\boards\st\nucleo_l152re\nucleo_l152re.dts:28 */
		green_led_0: led_0 {
			gpios = < &gpioa 0x5 0x0 >; /* in zephyr\boards\st\nucleo_l152re\nucleo_l152re.dts:29 */
			label = "User LD2";         /* in zephyr\boards\st\nucleo_l152re\nucleo_l152re.dts:30 */
		};
	};

	/* node '/gpio_keys' defined in zephyr\boards\st\nucleo_l152re\nucleo_l152re.dts:34 */
	gpio_keys {
		compatible = "gpio-keys"; /* in zephyr\boards\st\nucleo_l152re\nucleo_l152re.dts:35 */

		/* node '/gpio_keys/button' defined in zephyr\boards\st\nucleo_l152re\nucleo_l152re.dts:37 */
		user_button: button {
			label = "User";             /* in zephyr\boards\st\nucleo_l152re\nucleo_l152re.dts:38 */
			gpios = < &gpioc 0xd 0x1 >; /* in zephyr\boards\st\nucleo_l152re\nucleo_l152re.dts:39 */
			zephyr,code = < 0xb >;      /* in zephyr\boards\st\nucleo_l152re\nucleo_l152re.dts:40 */
		};
	};
};
